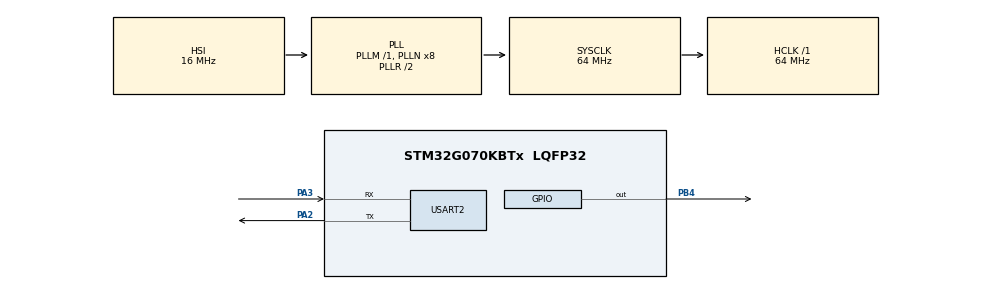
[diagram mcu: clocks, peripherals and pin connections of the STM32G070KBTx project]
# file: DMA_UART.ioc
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Dma.Request0=USART2_TX
Dma.Request1=USART2_RX
Dma.USART2_RX.1.Direction=DMA_PERIPH_TO_MEMORY
Dma.USART2_RX.1.EventEnable=DISABLE
Dma.USART2_RX.1.Instance=DMA1_Channel6
Dma.USART2_RX.1.MemDataAlignment=DMA_MDATAALIGN_BYTE
Dma.USART2_RX.1.MemInc=DMA_MINC_ENABLE
Dma.USART2_RX.1.Mode=DMA_NORMAL
Dma.USART2_RX.1.PeriphDataAlignment=DMA_PDATAALIGN_BYTE
Dma.USART2_RX.1.PeriphInc=DMA_PINC_DISABLE
Dma.USART2_RX.1.Polarity=HAL_DMAMUX_REQ_GEN_RISING
Dma.USART2_RX.1.Priority=DMA_PRIORITY_LOW
Dma.USART2_RX.1.RequestNumber=1
Dma.USART2_RX.1.SignalID=NONE
Dma.USART2_RX.1.SyncEnable=DISABLE
Dma.USART2_RX.1.SyncPolarity=HAL_DMAMUX_SYNC_NO_EVENT
Dma.USART2_RX.1.SyncRequestNumber=1
Dma.USART2_RX.1.SyncSignalID=NONE
Dma.USART2_TX.0.Direction=DMA_MEMORY_TO_PERIPH
Dma.USART2_TX.0.EventEnable=DISABLE
Dma.USART2_TX.0.Instance=DMA1_Channel4
Dma.USART2_TX.0.MemDataAlignment=DMA_MDATAALIGN_BYTE
Dma.USART2_TX.0.MemInc=DMA_MINC_ENABLE
Dma.USART2_TX.0.Mode=DMA_NORMAL
Dma.USART2_TX.0.PeriphDataAlignment=DMA_PDATAALIGN_BYTE
Dma.USART2_TX.0.PeriphInc=DMA_PINC_DISABLE
Dma.USART2_TX.0.Polarity=HAL_DMAMUX_REQ_GEN_RISING
Dma.USART2_TX.0.Priority=DMA_PRIORITY_LOW
Dma.USART2_TX.0.RequestNumber=1
Dma.USART2_TX.0.SignalID=NONE
Dma.USART2_TX.0.SyncEnable=DISABLE
Dma.USART2_TX.0.SyncPolarity=HAL_DMAMUX_SYNC_NO_EVENT
Dma.USART2_TX.0.SyncRequestNumber=1
Dma.USART2_TX.0.SyncSignalID=NONE
Mcu.Family=STM32G0
Mcu.Name=STM32G070KBTx
Mcu.Package=LQFP32
NVIC.DMA1_Ch4_7_DMAMUX1_OVR_IRQn=true\:0\:0\:false\:false\:true\:false\:true
NVIC.USART2_IRQn=true\:0\:0\:false\:false\:true\:true\:true
PA2.Mode=Asynchronous
PA2.Signal=USART2_TX
PA3.Mode=Asynchronous
PA3.Signal=USART2_RX
PB4.Signal=GPIO_Output
PC14-OSC32_IN\ (PC14).Mode=HSE-External-Clock-Source
PC14-OSC32_IN\ (PC14).Signal=RCC_OSC_IN
PC15-OSC32_OUT\ (PC15).Mode=OSC enable
PC15-OSC32_OUT\ (PC15).Signal=RCC_OSC_EN
ProjectManager.HeapSize=0x200
ProjectManager.StackSize=0x400
ProjectManager.TargetToolchain=MDK-ARM V5.27
RCC.ADCFreq_Value=64000000
RCC.AHBFreq_Value=64000000
RCC.CortexFreq_Value=64000000
RCC.EXTERNAL_CLOCK_VALUE=48000
RCC.HCLKFreq_Value=64000000
RCC.HSE_VALUE=8000000
RCC.HSI_VALUE=16000000
RCC.LSE_VALUE=32768
RCC.SYSCLKFreq_VALUE=64000000
RCC.SYSCLKSource=RCC_SYSCLKSOURCE_PLLCLK
RCC.VCOOutputFreq_Value=128000000
USART2.VirtualMode-Asynchronous=VM_ASYNC
VP_SYS_VS_DBSignals.Mode=DisableDeadBatterySignals
board=custom

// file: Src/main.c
/* USER CODE BEGIN Header */
/**
  ******************************************************************************
  * @file           : main.c
  * @brief          : Main program body
  ******************************************************************************
  * @attention
  *
  * <h2><center>&copy; Copyright (c) 2021 STMicroelectronics.
  * All rights reserved.</center></h2>
  *
  * This software component is licensed by ST under BSD 3-Clause license,
  * the "License"; You may not use this file except in compliance with the
  * License. You may obtain a copy of the License at:
  *                        opensource.org/licenses/BSD-3-Clause
  *
  ******************************************************************************
  */
/* USER CODE END Header */

#include "main.h"
#include "dma.h"
#include "usart.h"
#include "gpio.h"
#include "string.h"

/* USER CODE BEGIN PV */
uint8_t txdata[20];
uint8_t rxdata[20];
/* USER CODE END PV */

void SystemClock_Config(void);

int main(void)
{

  /* MCU Configuration--------------------------------------------------------*/

  /* Reset of all peripherals, Initializes the Flash interface and the Systick. */
  HAL_Init();

  /* Configure the system clock */
  SystemClock_Config();

  /* Initialize all configured peripherals */
  MX_GPIO_Init();
  MX_DMA_Init();
  MX_USART2_UART_Init();

  /* Infinite loop */
  /* USER CODE BEGIN WHILE */
	HAL_UART_Receive_DMA(&huart2,(uint8_t *)rxdata,11);	///使能串口DMA接收中断
//	__HAL_UART_ENABLE_IT(&huart2, UART_IT_IDLE);
//	__HAL_UART_CLEAR_IT(&huart2, UART_CLEAR_IDLEF);
  while (1)
  {
    /* USER CODE END WHILE */

  }
}

void HAL_UART_RxCpltCallback(UART_HandleTypeDef *huart)
{
	if(huart==&huart2)
	{
			memcpy(txdata,rxdata,11); ///将rxdata的前11个数据复制到txdata的前11位，该函数为标准C库的函数
		HAL_UART_Transmit_DMA(&huart2,(uint8_t *)txdata,sizeof(txdata)); ///使能串口DMA发送中断
		HAL_GPIO_TogglePin(GPIOB,GPIO_PIN_4); ///PB4管脚电平翻转
			HAL_UART_Receive_DMA(&huart2,(uint8_t *)rxdata,11); ///再次使能串口DMA接收中断
	}
}

void SystemClock_Config(void)
{
  RCC_OscInitTypeDef RCC_OscInitStruct = {0};
  RCC_ClkInitTypeDef RCC_ClkInitStruct = {0};
  RCC_PeriphCLKInitTypeDef PeriphClkInit = {0};

  /** Configure the main internal regulator output voltage
  */
  HAL_PWREx_ControlVoltageScaling(PWR_REGULATOR_VOLTAGE_SCALE1);
  /** Initializes the CPU, AHB and APB busses clocks
  */
  RCC_OscInitStruct.OscillatorType = RCC_OSCILLATORTYPE_HSI;
  RCC_OscInitStruct.HSIState = RCC_HSI_ON;
  RCC_OscInitStruct.HSIDiv = RCC_HSI_DIV1;
  RCC_OscInitStruct.HSICalibrationValue = RCC_HSICALIBRATION_DEFAULT;
  RCC_OscInitStruct.PLL.PLLState = RCC_PLL_ON;
  RCC_OscInitStruct.PLL.PLLSource = RCC_PLLSOURCE_HSI;
  RCC_OscInitStruct.PLL.PLLM = RCC_PLLM_DIV1;
  RCC_OscInitStruct.PLL.PLLN = 8;
  RCC_OscInitStruct.PLL.PLLP = RCC_PLLP_DIV2;
  RCC_OscInitStruct.PLL.PLLR = RCC_PLLR_DIV2;
  if (HAL_RCC_OscConfig(&RCC_OscInitStruct) != HAL_OK)
  {
    Error_Handler();
  }
  /** Initializes the CPU, AHB and APB busses clocks
  */
  RCC_ClkInitStruct.ClockType = RCC_CLOCKTYPE_HCLK|RCC_CLOCKTYPE_SYSCLK
                              |RCC_CLOCKTYPE_PCLK1;
  RCC_ClkInitStruct.SYSCLKSource = RCC_SYSCLKSOURCE_PLLCLK;
  RCC_ClkInitStruct.AHBCLKDivider = RCC_SYSCLK_DIV1;
  RCC_ClkInitStruct.APB1CLKDivider = RCC_HCLK_DIV1;

  if (HAL_RCC_ClockConfig(&RCC_ClkInitStruct, FLASH_LATENCY_2) != HAL_OK)
  {
    Error_Handler();
  }
  /** Initializes the peripherals clocks
  */
  PeriphClkInit.PeriphClockSelection = RCC_PERIPHCLK_USART2;
  PeriphClkInit.Usart2ClockSelection = RCC_USART2CLKSOURCE_PCLK1;
  if (HAL_RCCEx_PeriphCLKConfig(&PeriphClkInit) != HAL_OK)
  {
    Error_Handler();
  }
}

void Error_Handler(void)
{
}

/************************ (C) COPYRIGHT STMicroelectronics *****END OF FILE****/
